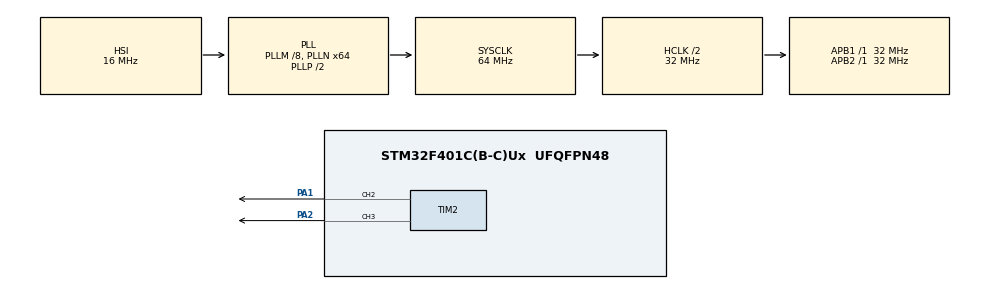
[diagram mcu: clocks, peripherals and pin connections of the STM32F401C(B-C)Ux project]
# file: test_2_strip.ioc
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Dma.Request0=TIM2_CH2/CH4
Dma.Request1=TIM2_CH3/UP
Dma.TIM2_CH2/CH4.0.Direction=DMA_MEMORY_TO_PERIPH
Dma.TIM2_CH2/CH4.0.FIFOMode=DMA_FIFOMODE_DISABLE
Dma.TIM2_CH2/CH4.0.Instance=DMA1_Stream6
Dma.TIM2_CH2/CH4.0.MemDataAlignment=DMA_MDATAALIGN_WORD
Dma.TIM2_CH2/CH4.0.MemInc=DMA_MINC_ENABLE
Dma.TIM2_CH2/CH4.0.Mode=DMA_CIRCULAR
Dma.TIM2_CH2/CH4.0.PeriphDataAlignment=DMA_PDATAALIGN_WORD
Dma.TIM2_CH2/CH4.0.PeriphInc=DMA_PINC_DISABLE
Dma.TIM2_CH2/CH4.0.Priority=DMA_PRIORITY_LOW
Dma.TIM2_CH3/UP.1.Direction=DMA_MEMORY_TO_PERIPH
Dma.TIM2_CH3/UP.1.FIFOMode=DMA_FIFOMODE_DISABLE
Dma.TIM2_CH3/UP.1.Instance=DMA1_Stream1
Dma.TIM2_CH3/UP.1.MemDataAlignment=DMA_MDATAALIGN_WORD
Dma.TIM2_CH3/UP.1.MemInc=DMA_MINC_ENABLE
Dma.TIM2_CH3/UP.1.Mode=DMA_CIRCULAR
Dma.TIM2_CH3/UP.1.PeriphDataAlignment=DMA_PDATAALIGN_WORD
Dma.TIM2_CH3/UP.1.PeriphInc=DMA_PINC_DISABLE
Dma.TIM2_CH3/UP.1.Priority=DMA_PRIORITY_LOW
FREERTOS.Tasks01=defaultTask,0,256,StartDefaultTask,Default,NULL,Dynamic,NULL,NULL;myTask02,0,256,StartTask02,Default,NULL,Dynamic,NULL,NULL
Mcu.Family=STM32F4
Mcu.Name=STM32F401C(B-C)Ux
Mcu.Package=UFQFPN48
NVIC.DMA1_Stream1_IRQn=true\:5\:0\:false\:false\:true\:true\:false\:true\:true
NVIC.DMA1_Stream6_IRQn=true\:5\:0\:false\:false\:true\:true\:false\:true\:true
NVIC.PriorityGroup=NVIC_PRIORITYGROUP_4
PA1.GPIO_ModeDefaultPP=GPIO_MODE_AF_OD
PA1.Signal=S_TIM2_CH2
PA13.Mode=Serial_Wire
PA13.Signal=SYS_JTMS-SWDIO
PA14.Mode=Serial_Wire
PA14.Signal=SYS_JTCK-SWCLK
PA2.GPIO_ModeDefaultPP=GPIO_MODE_AF_OD
PA2.Signal=S_TIM2_CH3
PC14-OSC32_IN.Mode=LSE-External-Oscillator
PC14-OSC32_IN.Signal=RCC_OSC32_IN
PC15-OSC32_OUT.Mode=LSE-External-Oscillator
PC15-OSC32_OUT.Signal=RCC_OSC32_OUT
PH0\ -\ OSC_IN.Mode=HSE-External-Oscillator
PH0\ -\ OSC_IN.Signal=RCC_OSC_IN
PH1\ -\ OSC_OUT.Mode=HSE-External-Oscillator
PH1\ -\ OSC_OUT.Signal=RCC_OSC_OUT
ProjectManager.HeapSize=0x500
ProjectManager.StackSize=0x1000
ProjectManager.TargetToolchain=MDK-ARM V5.32
RCC.48MHZClocksFreq_Value=32000000
RCC.AHBCLKDivider=RCC_SYSCLK_DIV2
RCC.AHBFreq_Value=32000000
RCC.APB1Freq_Value=32000000
RCC.APB1TimFreq_Value=32000000
RCC.APB2Freq_Value=32000000
RCC.APB2TimFreq_Value=32000000
RCC.CortexFreq_Value=32000000
RCC.HCLKFreq_Value=32000000
RCC.HSE_VALUE=25000000
RCC.HSI_VALUE=16000000
RCC.PLLM=8
RCC.PLLN=64
RCC.SYSCLKFreq_VALUE=64000000
RCC.SYSCLKSource=RCC_SYSCLKSOURCE_PLLCLK
RCC.VCOOutputFreq_Value=128000000
SH.S_TIM2_CH2.0=TIM2_CH2,PWM Generation2 CH2
SH.S_TIM2_CH3.0=TIM2_CH3,PWM Generation3 CH3
TIM2.Channel-PWM\ Generation2\ CH2=TIM_CHANNEL_2
TIM2.Channel-PWM\ Generation3\ CH3=TIM_CHANNEL_3
VP_FREERTOS_VS_CMSIS_V1.Mode=CMSIS_V1
board=custom

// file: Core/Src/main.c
/* USER CODE BEGIN Header */
/**
  ******************************************************************************
  * @file           : main.c
  * @brief          : Main program body
  ******************************************************************************
  * @attention
  *
  * Copyright (c) 2024 STMicroelectronics.
  * All rights reserved.
  *
  * This software is licensed under terms that can be found in the LICENSE file
  * in the root directory of this software component.
  * If no LICENSE file comes with this software, it is provided AS-IS.
  *
  ******************************************************************************
  */
/* USER CODE END Header */
#include "main.h"
#include "cmsis_os.h"

/* USER CODE BEGIN Includes */
#include "ARGB.h"
#include "libs.h"
/* USER CODE END Includes */

TIM_HandleTypeDef htim2;
DMA_HandleTypeDef hdma_tim2_ch2_ch4;
DMA_HandleTypeDef hdma_tim2_ch3_up;

osThreadId defaultTaskHandle;
osThreadId myTask02Handle;
/* USER CODE BEGIN PV */
ARGB_Strip my_strip;
ARGB_Strip my_strip_2;
/* USER CODE END PV */

void SystemClock_Config(void);
static void MX_GPIO_Init(void);
static void MX_DMA_Init(void);
static void MX_TIM2_Init(void);
void StartDefaultTask(void const * argument);
void StartTask02(void const * argument);

int main(void)
{

  /* MCU Configuration--------------------------------------------------------*/

  /* Reset of all peripherals, Initializes the Flash interface and the Systick. */
  HAL_Init();

  /* Configure the system clock */
  SystemClock_Config();

  /* Initialize all configured peripherals */
  MX_GPIO_Init();
  MX_DMA_Init();
  MX_TIM2_Init();

  /* Create the thread(s) */
  /* definition and creation of defaultTask */
  osThreadDef(defaultTask, StartDefaultTask, osPriorityNormal, 0, 256);
  defaultTaskHandle = osThreadCreate(osThread(defaultTask), NULL);

  /* definition and creation of myTask02 */
  osThreadDef(myTask02, StartTask02, osPriorityNormal, 0, 256);
  myTask02Handle = osThreadCreate(osThread(myTask02), NULL);

  /* Start scheduler */
  osKernelStart();

  /* We should never get here as control is now taken by the scheduler */

  /* Infinite loop */
  while (1)
  {

  }
}

void SystemClock_Config(void)
{
  RCC_OscInitTypeDef RCC_OscInitStruct = {0};
  RCC_ClkInitTypeDef RCC_ClkInitStruct = {0};

  /** Configure the main internal regulator output voltage
  */
  __HAL_RCC_PWR_CLK_ENABLE();
  __HAL_PWR_VOLTAGESCALING_CONFIG(PWR_REGULATOR_VOLTAGE_SCALE2);

  /** Initializes the RCC Oscillators according to the specified parameters
  * in the RCC_OscInitTypeDef structure.
  */
  RCC_OscInitStruct.OscillatorType = RCC_OSCILLATORTYPE_HSI;
  RCC_OscInitStruct.HSIState = RCC_HSI_ON;
  RCC_OscInitStruct.HSICalibrationValue = RCC_HSICALIBRATION_DEFAULT;
  RCC_OscInitStruct.PLL.PLLState = RCC_PLL_ON;
  RCC_OscInitStruct.PLL.PLLSource = RCC_PLLSOURCE_HSI;
  RCC_OscInitStruct.PLL.PLLM = 8;
  RCC_OscInitStruct.PLL.PLLN = 64;
  RCC_OscInitStruct.PLL.PLLP = RCC_PLLP_DIV2;
  RCC_OscInitStruct.PLL.PLLQ = 4;
  if (HAL_RCC_OscConfig(&RCC_OscInitStruct) != HAL_OK)
  {
    Error_Handler();
  }

  /** Initializes the CPU, AHB and APB buses clocks
  */
  RCC_ClkInitStruct.ClockType = RCC_CLOCKTYPE_HCLK|RCC_CLOCKTYPE_SYSCLK
                              |RCC_CLOCKTYPE_PCLK1|RCC_CLOCKTYPE_PCLK2;
  RCC_ClkInitStruct.SYSCLKSource = RCC_SYSCLKSOURCE_PLLCLK;
  RCC_ClkInitStruct.AHBCLKDivider = RCC_SYSCLK_DIV2;
  RCC_ClkInitStruct.APB1CLKDivider = RCC_HCLK_DIV1;
  RCC_ClkInitStruct.APB2CLKDivider = RCC_HCLK_DIV1;

  if (HAL_RCC_ClockConfig(&RCC_ClkInitStruct, FLASH_LATENCY_1) != HAL_OK)
  {
    Error_Handler();
  }
}

static void MX_TIM2_Init(void)
{

  TIM_MasterConfigTypeDef sMasterConfig = {0};
  TIM_OC_InitTypeDef sConfigOC = {0};

  htim2.Instance = TIM2;
  htim2.Init.Prescaler = 0;
  htim2.Init.CounterMode = TIM_COUNTERMODE_UP;
  htim2.Init.Period = 4294967295;
  htim2.Init.ClockDivision = TIM_CLOCKDIVISION_DIV1;
  htim2.Init.AutoReloadPreload = TIM_AUTORELOAD_PRELOAD_DISABLE;
  if (HAL_TIM_PWM_Init(&htim2) != HAL_OK)
  {
    Error_Handler();
  }
  sMasterConfig.MasterOutputTrigger = TIM_TRGO_RESET;
  sMasterConfig.MasterSlaveMode = TIM_MASTERSLAVEMODE_DISABLE;
  if (HAL_TIMEx_MasterConfigSynchronization(&htim2, &sMasterConfig) != HAL_OK)
  {
    Error_Handler();
  }
  sConfigOC.OCMode = TIM_OCMODE_PWM1;
  sConfigOC.Pulse = 0;
  sConfigOC.OCPolarity = TIM_OCPOLARITY_HIGH;
  sConfigOC.OCFastMode = TIM_OCFAST_DISABLE;
  if (HAL_TIM_PWM_ConfigChannel(&htim2, &sConfigOC, TIM_CHANNEL_2) != HAL_OK)
  {
    Error_Handler();
  }
  if (HAL_TIM_PWM_ConfigChannel(&htim2, &sConfigOC, TIM_CHANNEL_3) != HAL_OK)
  {
    Error_Handler();
  }
  HAL_TIM_MspPostInit(&htim2);

}

static void MX_DMA_Init(void)
{

  /* DMA controller clock enable */
  __HAL_RCC_DMA1_CLK_ENABLE();

  /* DMA interrupt init */
  /* DMA1_Stream1_IRQn interrupt configuration */
  HAL_NVIC_SetPriority(DMA1_Stream1_IRQn, 5, 0);
  HAL_NVIC_EnableIRQ(DMA1_Stream1_IRQn);
  /* DMA1_Stream6_IRQn interrupt configuration */
  HAL_NVIC_SetPriority(DMA1_Stream6_IRQn, 5, 0);
  HAL_NVIC_EnableIRQ(DMA1_Stream6_IRQn);

}

static void MX_GPIO_Init(void)
{

  /* GPIO Ports Clock Enable */
  __HAL_RCC_GPIOC_CLK_ENABLE();
  __HAL_RCC_GPIOH_CLK_ENABLE();
  __HAL_RCC_GPIOA_CLK_ENABLE();

}

void StartDefaultTask(void const * argument)
{
  /* USER CODE BEGIN 5 */
	my_strip.tim_handle = &htim2;
my_strip.dma_handle = &hdma_tim2_ch2_ch4;
my_strip.buf_counter = 0;
my_strip.brightness = 255;
my_strip.state = ARGB_READY;
my_strip.num_pixels = 16;
my_strip.apb = 2;
my_strip.tim_ch = TIM_CHANNEL_2;
my_strip.rgb_buf = (uint8_t *)malloc(3 * my_strip.num_pixels * sizeof(uint8_t));
my_strip.pwm_buf = (uint32_t *)malloc(3*8*2 * sizeof(uint32_t));
	hdma_tim2_ch2_ch4.Parent_strip = &my_strip;
					ARGB_Init(&my_strip);
					ARGB_SetBrightness(&my_strip, 20);
  /* Infinite loop */
  for(;;)
  {
					ARGB_Clear(&my_strip);
					while (!ARGB_Show(&my_strip));
					ARGB_FillRGB(&my_strip, 200, 20, 20);
					while (!ARGB_Show(&my_strip));
					HAL_Delay(500);

					ARGB_Clear(&my_strip);
					while (!ARGB_Show(&my_strip));
					ARGB_FillRGB(&my_strip, 20, 200, 20);
					while (!ARGB_Show(&my_strip));
					HAL_Delay(500);
    osDelay(1);
  }
  /* USER CODE END 5 */
}

void StartTask02(void const * argument)
{
  /* USER CODE BEGIN StartTask02 */
	my_strip_2.tim_handle = &htim2;
my_strip_2.dma_handle = &hdma_tim2_ch3_up;
my_strip_2.buf_counter = 0;
my_strip_2.brightness = 255;
my_strip_2.state = ARGB_READY;
my_strip_2.num_pixels = 16;
my_strip_2.apb = 2;
my_strip_2.tim_ch = TIM_CHANNEL_3;
my_strip_2.rgb_buf = (uint8_t *)malloc(3 * my_strip_2.num_pixels * sizeof(uint8_t));
my_strip_2.pwm_buf = (uint32_t *)malloc(3*8*2 * sizeof(uint32_t));
	ARGB_Init(&my_strip_2);
					ARGB_SetBrightness(&my_strip_2, 20);
	hdma_tim2_ch3_up.Parent_strip = &my_strip_2;
  /* Infinite loop */
  for(;;)
  {

		ARGB_Clear(&my_strip_2);

		while (!ARGB_Show(&my_strip_2));

		ARGB_FillRGB(&my_strip_2, 20, 200, 20);

		while (!ARGB_Show(&my_strip_2));

		HAL_Delay(500);

		ARGB_Clear(&my_strip_2);

		while (!ARGB_Show(&my_strip_2));

		ARGB_FillRGB(&my_strip_2, 200, 20, 20);

		while (!ARGB_Show(&my_strip_2));

		HAL_Delay(500);
    osDelay(1);
  }
  /* USER CODE END StartTask02 */
}

void Error_Handler(void)
{
  __disable_irq();
  while (1)
  {
  }
}
